# ioASM9260T register map
Registers from a debugger description file.
Registers are 32-bit, access not given, no defined reset value unless marked. A register's access mark holds for its fields unless they carry their own. Addresses are absolute; registers are grouped by the start of their names; lines under a group give offsets from that group; [hi:lo] are bit positions; {n}, {i} and the like mark numbered series; 'fields as' and 'values as' point back to an identical list; <NAME> marks a mode.

## SFR
0x80040000 PRESETCTRL0
0x80040010 PRESETCTRL1
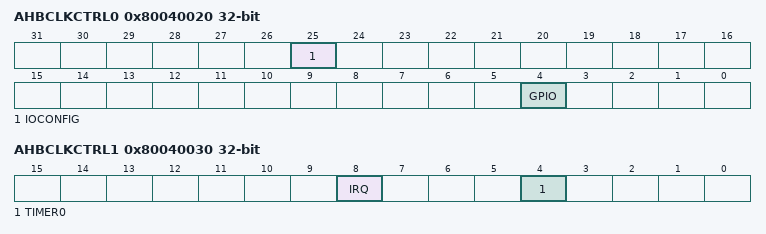
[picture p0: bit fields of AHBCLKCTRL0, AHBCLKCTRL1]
0x80040020 AHBCLKCTRL0
  [25] IOCONFIG, [4] GPIO
0x80040030 AHBCLKCTRL1
  [8] IRQ, [4] TIMER0
0x80040100 SYSPLLCTRL
0x80040110 SYSRSTSTAT
0x80040120 MAINCLKSEL
0x80040124 MAINCLKUEN
0x80040128 UARTCLKSEL
0x8004012C UARTCLKUEN
0x8004017C CPUCLKDIV
0x80040180 SYSAHBCLKDIV
{0x80040198+4i} UART{i}CLKDIV (i=0..9)
0x80040400 DEVICEID
0x80040500 PCON

## HW
{0x50000000+0x10000*i} HW_GPIO_DATA{i} (i=0..3)
{0x50008000+0x10000*i} HW_GPIO_DIR{i} (i=0..3)
{0x50008010+0x10000*i} HW_GPIO_IS{i} (i=0..3)
{0x50008020+0x10000*i} HW_GPIO_IBE{i} (i=0..3)
{0x50008030+0x10000*i} HW_GPIO_IEV{i} (i=0..3)
{0x50008040+0x10000*i} HW_GPIO_IE{i} (i=0..3)
{0x50008050+0x10000*i} HW_GPIO_IRS{i} (i=0..3)
{0x50008060+0x10000*i} HW_GPIO_MIS{i} (i=0..3)
{0x50008070+0x10000*i} HW_GPIO_IC{i} (i=0..3)
{0x50008080+0x10000*i} HW_GPIO_DATAMASK{i} (i=0..3)
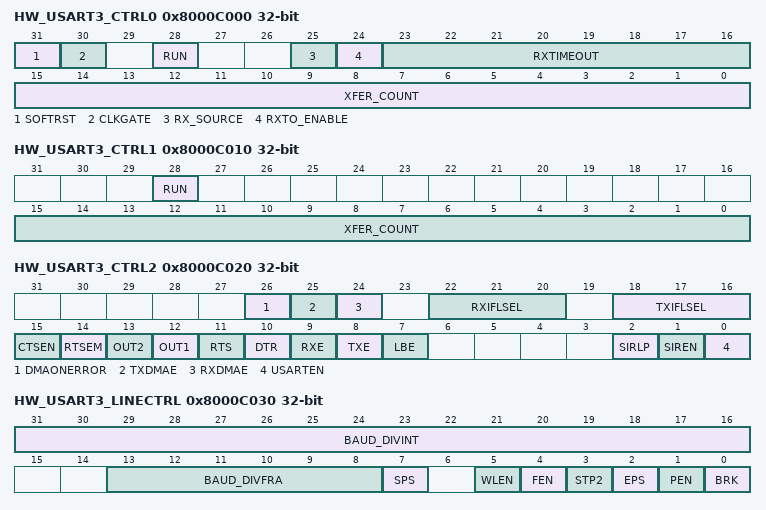
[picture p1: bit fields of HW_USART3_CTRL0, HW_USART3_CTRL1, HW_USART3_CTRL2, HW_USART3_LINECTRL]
0x8000C000 HW_USART3_CTRL0
  [31] SOFTRST, [30] CLKGATE, [28] RUN, [25] RX_SOURCE, [24] RXTO_ENABLE, [23:16] RXTIMEOUT, [15:0] XFER_COUNT
0x8000C010 HW_USART3_CTRL1
  [28] RUN, [15:0] XFER_COUNT
0x8000C020 HW_USART3_CTRL2
  [26] DMAONERROR, [25] TXDMAE, [24] RXDMAE, [22:20] RXIFLSEL, [18:16] TXIFLSEL, [15] CTSEN, [14] RTSEM, [13] OUT2, [12] OUT1, [11] RTS, [10] DTR, [9] RXE, [8] TXE, [7] LBE, [2] SIRLP, [1] SIREN, [0] USARTEN
0x8000C030 HW_USART3_LINECTRL
  [31:16] BAUD_DIVINT, [13:8] BAUD_DIVFRA, [7] SPS, [5] WLEN, [4] FEN, [3] STP2, [2] EPS, [1] PEN, [0] BRK
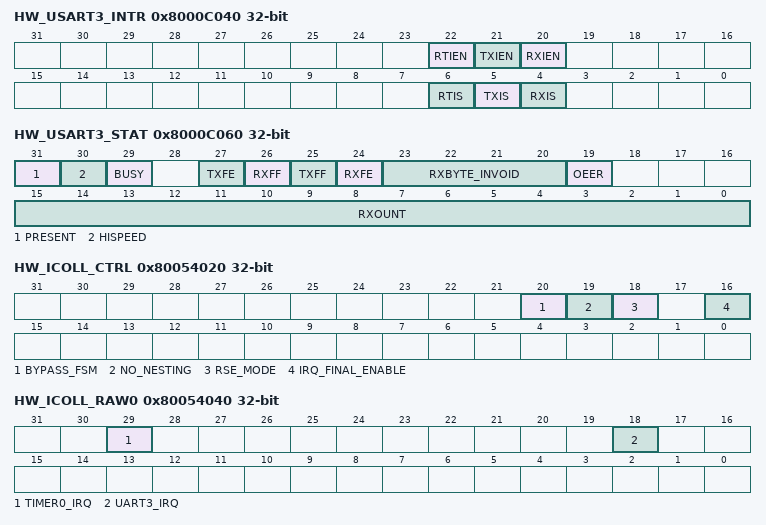
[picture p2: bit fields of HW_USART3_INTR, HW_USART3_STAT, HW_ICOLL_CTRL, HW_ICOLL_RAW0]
0x8000C040 HW_USART3_INTR
  [22] RTIEN, [21] TXIEN, [20] RXIEN, [6] RTIS, [5] TXIS, [4] RXIS
0x8000C050 HW_USART3_DATA
0x8000C060 HW_USART3_STAT
  [31] PRESENT, [30] HISPEED, [29] BUSY, [27] TXFE, [26] RXFF, [25] TXFF, [24] RXFE, [23:20] RXBYTE_INVOID, [19] OEER, [15:0] RXOUNT
0x8000C070 HW_USART3_DEBUG
0x8000C080 HW_USART3_ILPR
0x8000C090 HW_USART3_RS485CTRL
0x8000C0A0 HW_USART3_RS485ADRMATCH
0x8000C0B0 HW_USART3_RS485DLY
0x8000C0C0 HW_USART3_AUTOBAUD
0x8000C0D0 HW_USART3_CTRL3
0x8000C0E0 HW_USART3_ISO7816CTRL
0x8000C0F0 HW_USART3_ISO7816ERRCNT
0x8000C100 HW_USART3_ISO7816STAT
0x80054000 HW_ICOLL_VECTOR
0x80054010 HW_ICOLL_LEVELACK
0x80054020 HW_ICOLL_CTRL
  [20] BYPASS_FSM, [19] NO_NESTING, [18] RSE_MODE, [16] IRQ_FINAL_ENABLE
0x80054030 HW_ICOLL_STAT
  [5:0] vector_number
0x80054040 HW_ICOLL_RAW0
  [29] TIMER0_IRQ, [18] UART3_IRQ
0x80054050 HW_ICOLL_RAW1
{0x80054060+0x10*i} HW_ICOLL_PRIORITY{i} (i=0..15)
0x80054160 HW_ICOLL_VBASE
0x80054170 HW_ICOLL_DEBUG
0x80054180 HW_ICOLL_DBGREAD0
0x80054190 HW_ICOLL_DBGREAD1
0x800541A0 HW_ICOLL_DBGFLAG
0x800541B0 HW_ICOLL_DBGREQUEST0
0x800541C0 HW_ICOLL_DBGREQUEST1
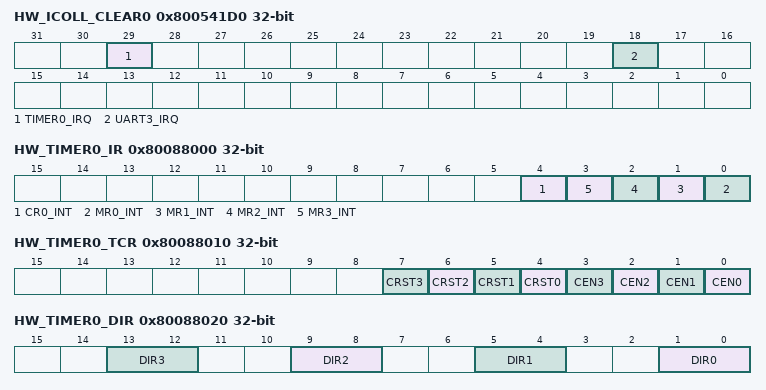
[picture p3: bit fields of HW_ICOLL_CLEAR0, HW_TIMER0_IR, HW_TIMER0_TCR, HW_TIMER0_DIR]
0x800541D0 HW_ICOLL_CLEAR0
  [29] TIMER0_IRQ, [18] UART3_IRQ
0x800541E0 HW_ICOLL_CLEAR1
0x800541F0 HW_ICOLL_UNDEF_VECTOR
0x80088000 HW_TIMER0_IR
  [4] CR0_INT, [n] MR{n}_INT (n=0..3)
0x80088010 HW_TIMER0_TCR
  [n+4] CRST{n} (n=0..3), [n] CEN{n} (n=0..3)
0x80088020 HW_TIMER0_DIR
  [4n+1:4n] DIR{n} (n=0..3)
{0x80088030+0x10*i} HW_TIMER0_TC{i} (i=0..3)
0x80088070 HW_TIMER0_PR
0x80088080 HW_TIMER0_PC
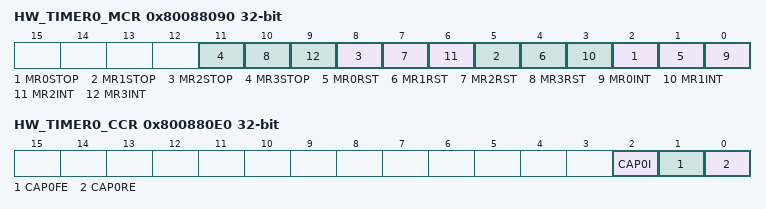
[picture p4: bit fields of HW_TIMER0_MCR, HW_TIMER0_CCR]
0x80088090 HW_TIMER0_MCR
  [3n+2] MR{n}STOP (n=0..3), [3n+1] MR{n}RST (n=0..3), [3n] MR{n}INT (n=0..3)
{0x800880A0+0x10*i} HW_TIMER0_MR{i} (i=0..3)
0x800880E0 HW_TIMER0_CCR
  [2] CAP0I, [1] CAP0FE, [0] CAP0RE
{0x800880F0+0x10*i} HW_TIMER0_CR{i} (i=0..3)
0x80088130 HW_TIMER0_EMR
{0x80088140+0x10*i} HW_TIMER0_PWMTH{i} (i=0..3)
0x80088180 HW_TIMER0_CTCR
0x80088190 HW_TIMER0_PWMC
